# Polarfire SoC register map
Vendor: Microchip; File version: 1.0
CPU: Microchip PolarFire SoC 1.0, little endian
Registers are 32-bit, read-write, reset 0x0 unless marked. A register's access mark holds for its fields unless they carry their own. Offsets are from the block's base; [hi:lo] are bit positions; {n}, {i} and the like mark numbered series; 'fields as' and 'values as' point back to an identical list.

## CFG_DDR_SGMII_PHY — CFG_DDR_SGMII_PHY Controller
Base 0x20007000
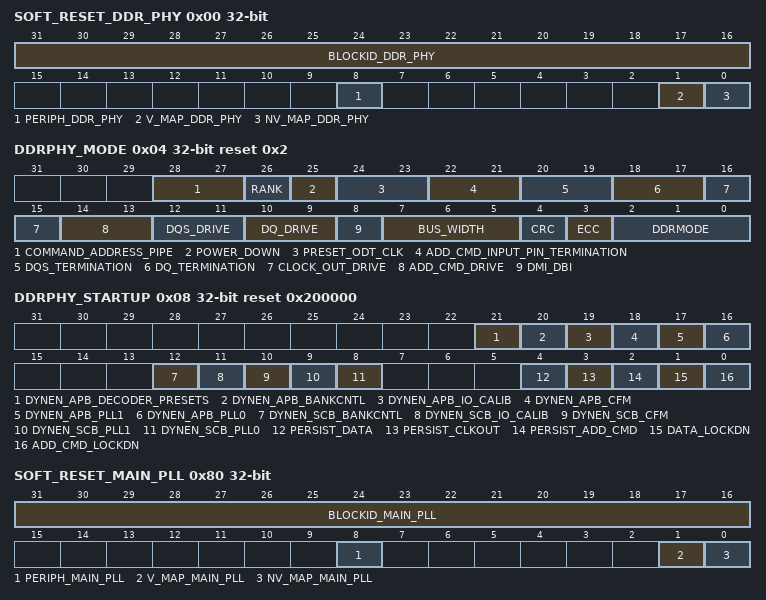
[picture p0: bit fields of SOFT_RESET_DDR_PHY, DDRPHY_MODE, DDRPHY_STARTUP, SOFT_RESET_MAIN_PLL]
0x00 SOFT_RESET_DDR_PHY — Compulsory register for all SCB slaves, facilitating global soft reset.
  [31:16] BLOCKID_DDR_PHY ro — This returns the block type and chip location. The form of BLOCKID = {4'h0, SLVTYPE, CHIPID, SUBID}. SLVTYPE=4'h2 for PCIESS MAIN. CHIPID=4'h0 for PCIESS. SUBID=4'h4 for the MAIN page.
  [8] PERIPH_DDR_PHY — This asserts functional reset of the peripheral block. It is asserted and left asserted at power-up. Write 0 Write 1
  [1] V_MAP_DDR_PHY — Resets all the volatile register bits. Write 0 Write 1
  [0] NV_MAP_DDR_PHY — Resets all the non-volatile register bits (e.g. RW-P bits). Write 0 Write 1
0x04 DDRPHY_MODE reset 0x2
  [28:27] COMMAND_ADDRESS_PIPE — Added Command/Address pipelining
  [26] RANK — select rank
  [25] POWER_DOWN — Power down DDR PHY
  [24:23] PRESET_ODT_CLK — Default, +1,+2, -1 increment settings
  [22:21] ADD_CMD_INPUT_PIN_TERMINATION — Default, +1,+2, -1 increment settings
  [20:19] DQS_TERMINATION — Default, +1,+2, -1 increment settings
  [18:17] DQ_TERMINATION — Default, +1,+2, -1 increment settings
  [16:15] CLOCK_OUT_DRIVE — Default, +1,+2, -1 increment settings
  [14:13] ADD_CMD_DRIVE — Default, +1,+2, -1 increment settings
  [12:11] DQS_DRIVE — Default, +1,+2, -1 increment settings
  [10:9] DQ_DRIVE — Default, +1,+2, -1 increment settings
  [8] DMI_DBI — Data mask or Data bus inversion on/off
  [7:5] BUS_WIDTH — DDR bus width (16 or 32)
  [4] CRC — CRC on/off
  [3] ECC — ECC on/off
  [2:0] DDRMODE — DDR3, DDR3L, DDR4, LPDDR3, LPDDR4 decode. "000 ddr3 001 ddr33L 010 ddr4 011 LPDDR3 100 LPDDR4"
0x08 DDRPHY_STARTUP reset 0x200000
  [21] DYNEN_APB_DECODER_PRESETS — Enable APB DECODER PRESET bit over rides
  [20] DYNEN_APB_BANKCNTL — Enable APB BANKCNTL bit over rides
  [19] DYNEN_APB_IO_CALIB — Enable APB IO CALIB bit over rides
  [18] DYNEN_APB_CFM — Enable APB CFM bit over rides
  [17] DYNEN_APB_PLL1 — Enable APB PLL1 bit over rides
  [16] DYNEN_APB_PLL0 — Enable APB PLL0 bit over rides
  [12] DYNEN_SCB_BANKCNTL — Enable SCB BANKCNTL bit over rides
  [11] DYNEN_SCB_IO_CALIB — Enable SCB IO CALIB bit over rides
  [10] DYNEN_SCB_CFM — Enable SCB CFM bit over rides
  [9] DYNEN_SCB_PLL1 — Enable SCB PLL1 bit over rides
  [8] DYNEN_SCB_PLL0 — Enable SCB PLL0 bit over rides
  [4] PERSIST_DATA — Persist all DATA Dqa dn DQS bits. When 1: write RPC_lp_persist_dqs to 1 write RPC_lp_persist_dqsp to 1 write RPC_lp_persist_dqsn to 1 else 0
  [3] PERSIST_CLKOUT — Persist all clkout bits. When 1: write RPC_lp_persist_clkp to 1 write RPC_lp_persist_clkn to 1 else 0
  [2] PERSIST_ADD_CMD — Persit all Addcmd bits . When 1: write RPC_lp_persist_addcmd to 1 else 0
  [1] DATA_LOCKDN — Data bits honor Lockdn clobal signal
  [0] ADD_CMD_LOCKDN — Addcmd bits honor Lockdn global signal
0x0C SPARE_0 — spare logic
  [15:0] SPARE_0 — Spare register bits
0x80 SOFT_RESET_MAIN_PLL — This is a compulsory register for all SCB slaves and must be at the same offset in all slaves to facilitate global soft reset of all SCB registers with a single broadcast write from the SCB master.
  [31:16] BLOCKID_MAIN_PLL ro — This returns the block type and chip location. (IO SCB bus only) Read 0x0000
  [8] PERIPH_MAIN_PLL — This asserts the functional reset of the block. It is asserted at power up. When written is stays asserted until written to 0. Write 0 Write 1
  [1] V_MAP_MAIN_PLL — This when asserted resets all the register bits apart from the non-volatile registers@ the bit self clears. i.e. is similar to a W1P bit Write 0 Write 1
  [0] NV_MAP_MAIN_PLL — This when asserted resets all the non-volatile register bits e.g. RW-P bits@ the bit self clears i.e. is similar to a W1P bit Write 0 Write 1
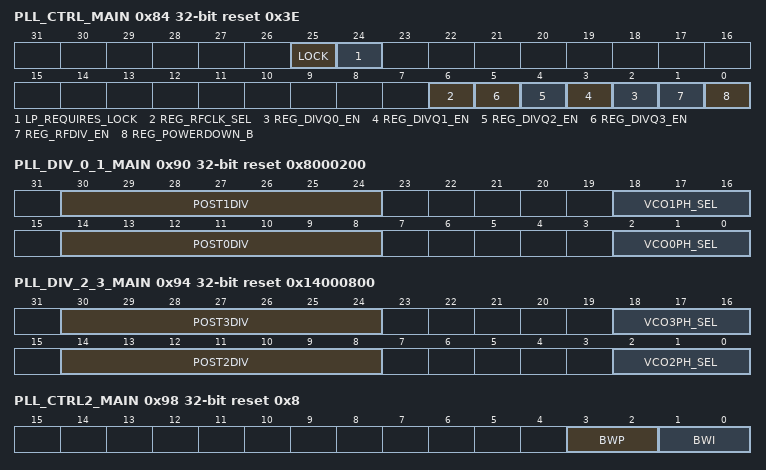
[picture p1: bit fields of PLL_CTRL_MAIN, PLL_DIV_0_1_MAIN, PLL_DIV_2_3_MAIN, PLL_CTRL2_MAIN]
0x84 PLL_CTRL_MAIN reset 0x3E — PLL control register
  [25] LOCK ro — Status of PLL lock
  [24] LP_REQUIRES_LOCK
  [6] REG_RFCLK_SEL
  [n+2] REG_DIVQ{n}_EN (n=0..3)
  [1] REG_RFDIV_EN
  [0] REG_POWERDOWN_B
0x88 PLL_REF_FB_MAIN reset 0x100 — PLL reference and feedback registers
  [13:8] RFDIV
0x8C PLL_FRACN_MAIN ro — PLL fractional register
0x90 PLL_DIV_0_1_MAIN reset 0x8000200 — PLL 0/1 division registers
  [30:24] POST1DIV, [18:16] VCO1PH_SEL ro, [14:8] POST0DIV, [2:0] VCO0PH_SEL ro
0x94 PLL_DIV_2_3_MAIN reset 0x14000800 — PLL 2/3 division registers
  [30:24] POST3DIV, [18:16] VCO3PH_SEL ro, [14:8] POST2DIV, [2:0] VCO2PH_SEL ro
0x98 PLL_CTRL2_MAIN reset 0x8 — PLL control register
  [3:2] BWP, [1:0] BWI
0x9C PLL_CAL_MAIN ro — PLL calibration register
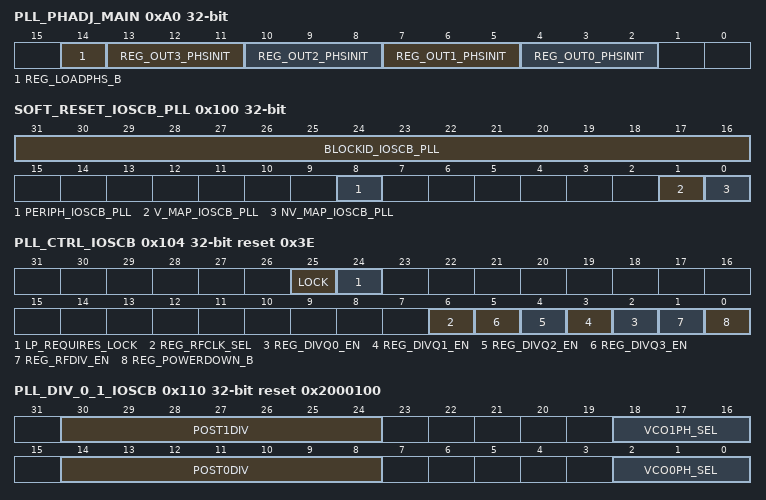
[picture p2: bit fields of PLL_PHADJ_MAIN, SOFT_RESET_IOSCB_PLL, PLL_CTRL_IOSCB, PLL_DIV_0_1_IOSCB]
0xA0 PLL_PHADJ_MAIN — PLL phase registers
  [14] REG_LOADPHS_B, [3n+4:3n+2] REG_OUT{n}_PHSINIT (n=0..3)
0xA4 SSCG_REG_0_MAIN ro — SSCG registers 0
0xA8 SSCG_REG_1_MAIN ro — SSCG registers 1
0xAC SSCG_REG_2_MAIN reset 0x30 — SSCG registers 2
  [11:0] INTIN
0xB0 SSCG_REG_3_MAIN ro — SSCG registers 3
0xB4 RPC_RESET_MAIN_PLL
  [0] SOFT_RESET_PERIPH_MAIN_PLL — RPC reset register
0x100 SOFT_RESET_IOSCB_PLL — This is a compulsory register for all SCB slaves and must be at the same offset in all slaves to facilitate global soft reset of all SCB registers with a single broadcast write from the SCB master.
  [31:16] BLOCKID_IOSCB_PLL ro — This returns the block type and chip location. (IO SCB bus only) Read 0x0000
  [8] PERIPH_IOSCB_PLL — This asserts the functional reset of the block. It is asserted at power up. When written is stays asserted until written to 0. Write 0 Write 1
  [1] V_MAP_IOSCB_PLL — This when asserted resets all the register bits apart from the non-volatile registers@ the bit self clears. i.e. is similar to a W1P bit Write 0 Write 1
  [0] NV_MAP_IOSCB_PLL — This when asserted resets all the non-volatile register bits e.g. RW-P bits@ the bit self clears i.e. is similar to a W1P bit Write 0 Write 1
0x104 PLL_CTRL_IOSCB reset 0x3E — PLL control register
  fields as PLL_CTRL_MAIN
0x108 PLL_REF_FB_IOSCB reset 0x100 — PLL reference and feedback registers
  [13:8] RFDIV
0x10C PLL_FRACN_IOSCB ro — PLL fractional register
0x110 PLL_DIV_0_1_IOSCB reset 0x2000100 — PLL 0/1 division registers
  fields as PLL_DIV_0_1_MAIN
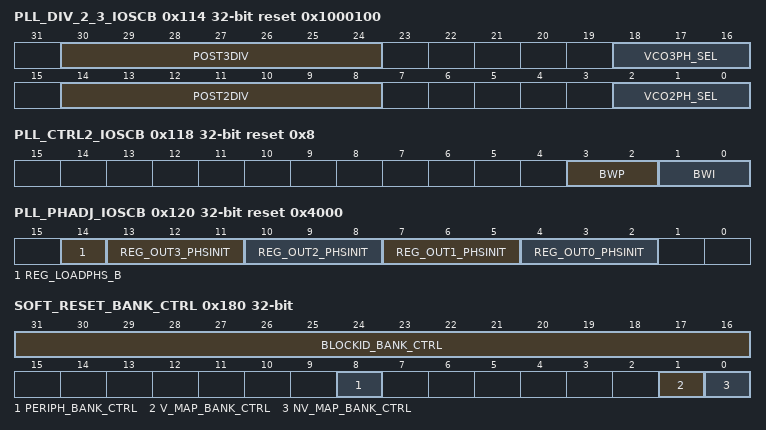
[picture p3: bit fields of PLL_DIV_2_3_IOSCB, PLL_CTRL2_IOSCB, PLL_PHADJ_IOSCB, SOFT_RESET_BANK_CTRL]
0x114 PLL_DIV_2_3_IOSCB reset 0x1000100 — PLL 2/3 division registers
  fields as PLL_DIV_2_3_MAIN
0x118 PLL_CTRL2_IOSCB reset 0x8 — PLL control register
  [3:2] BWP, [1:0] BWI
0x11C PLL_CAL_IOSCB ro — PLL calibration register
0x120 PLL_PHADJ_IOSCB reset 0x4000 — PLL phase registers
  [14] REG_LOADPHS_B, [3n+4:3n+2] REG_OUT{n}_PHSINIT (n=0..3)
0x124 SSCG_REG_0_IOSCB ro — SSCG registers 0
0x128 SSCG_REG_1_IOSCB ro — SSCG registers 1
0x12C SSCG_REG_2_IOSCB reset 0x20 — SSCG registers 2
  [11:0] INTIN
0x130 SSCG_REG_3_IOSCB ro — SSCG registers 3
0x134 RPC_RESET_IOSCB
  [0] SOFT_RESET_PERIPH_IOSCB — RPC reset register
0x180 SOFT_RESET_BANK_CTRL — This is a compulsory register for all SCB slaves and must be at the same offset in all slaves to facilitate global soft reset of all SCB registers with a single broadcast write from the SCB master.
  [31:16] BLOCKID_BANK_CTRL ro — This returns the block type and chip location. (IO SCB bus only) Read 0x0000
  [8] PERIPH_BANK_CTRL — This asserts the functional reset of the block. It is asserted at power up. When written is stays asserted until written to 0. Write 0 Write 1
  [1] V_MAP_BANK_CTRL — This when asserted resets all the register bits apart from the non-volatile registers@ the bit self clears. i.e. is similar to a W1P bit Write 0 Write 1
  [0] NV_MAP_BANK_CTRL — This when asserted resets all the non-volatile register bits e.g. RW-P bits@ the bit self clears i.e. is similar to a W1P bit Write 0 Write 1
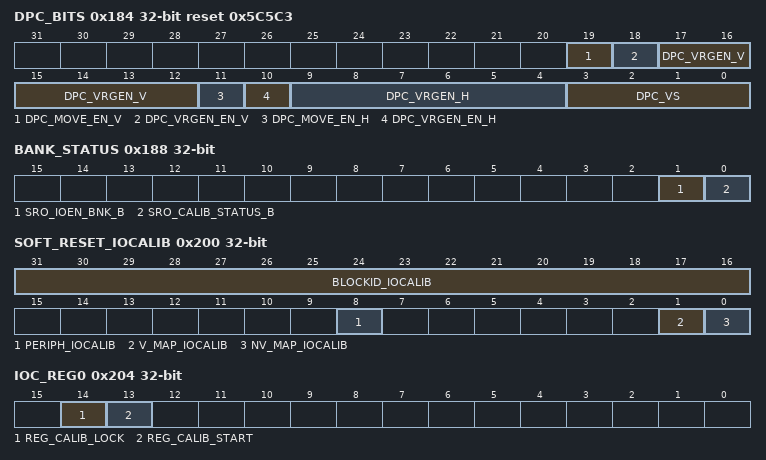
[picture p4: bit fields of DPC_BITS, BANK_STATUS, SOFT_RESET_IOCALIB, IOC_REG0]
0x184 DPC_BITS reset 0x5C5C3
  [19] DPC_MOVE_EN_V — enable dynamic control of vrgen circuit for ADDCMD pins
  [18] DPC_VRGEN_EN_V — enable vref generator for ADDCMD pins
  [17:12] DPC_VRGEN_V — reference voltage ratio setting for ADDCMD pins
  [11] DPC_MOVE_EN_H — enable dynamic control of vrgen circuit for DQ/DQS pins
  [10] DPC_VRGEN_EN_H — enable vref generator for DQ/DQS pins
  [9:4] DPC_VRGEN_H — reference voltage ratio setting for DQ/DQS pins
  [3:0] DPC_VS — bank voltage select for pvt calibration
0x188 BANK_STATUS ro — Bank Complete Registers
  [1] SRO_IOEN_BNK_B — Bank power on complete (active low for polling)
  [0] SRO_CALIB_STATUS_B — Bank calibration complete (active low for polling)
0x18C RPC_RESET_BANK_CTRL
  [0] SOFT_RESET_PERIPH_BANK_CTRL — RPC reset register
0x200 SOFT_RESET_IOCALIB — This is a compulsory register for all SCB slaves and must be at the same offset in all slaves to facilitate global soft reset of all SCB registers with a single broadcast write from the SCB master.
  [31:16] BLOCKID_IOCALIB ro — This returns the block type and chip location. (IO SCB bus only) Read 0x0000
  [8] PERIPH_IOCALIB — This asserts the functional reset of the block. It is asserted at power up. When written is stays asserted until written to 0. Write 0 Write 1
  [1] V_MAP_IOCALIB — This when asserted resets all the register bits apart from the non-volatile registers@ the bit self clears. i.e. is similar to a W1P bit Write 0 Write 1
  [0] NV_MAP_IOCALIB — This when asserted resets all the non-volatile register bits e.g. RW-P bits@ the bit self clears i.e. is similar to a W1P bit Write 0 Write 1
0x204 IOC_REG0 — IO calib control register0
  [14] REG_CALIB_LOCK, [13] REG_CALIB_START
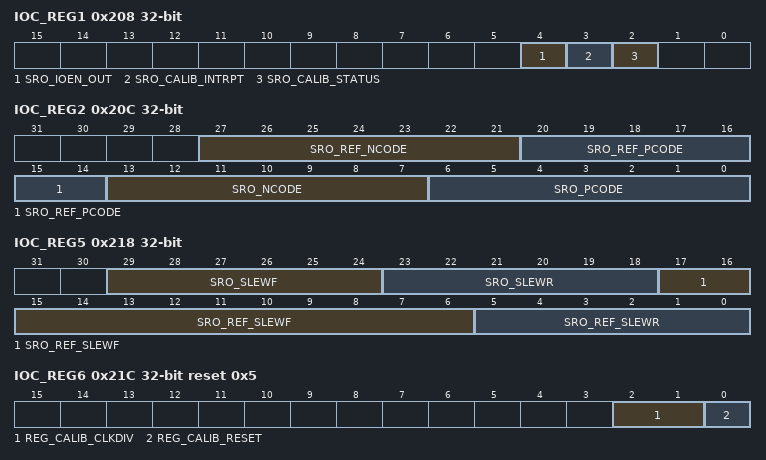
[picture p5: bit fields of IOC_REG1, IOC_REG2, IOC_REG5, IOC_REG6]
0x208 IOC_REG1 ro — IO calib control register1
  [4] SRO_IOEN_OUT, [3] SRO_CALIB_INTRPT, [2] SRO_CALIB_STATUS
0x20C IOC_REG2 ro — IO calib control register2
  [27:21] SRO_REF_NCODE, [20:14] SRO_REF_PCODE, [13:7] SRO_NCODE, [6:0] SRO_PCODE
0x210 IOC_REG3 ro — IO calib control register3
0x214 IOC_REG4 ro — IO calib control register4
0x218 IOC_REG5 ro — IO calib control register5
  [29:24] SRO_SLEWF, [23:18] SRO_SLEWR, [17:6] SRO_REF_SLEWF, [5:0] SRO_REF_SLEWR
0x21C IOC_REG6 reset 0x5 — IO calibr control resgister6
  [2:1] REG_CALIB_CLKDIV, [0] REG_CALIB_RESET
0x220 RPC_RESET_IOCALIB
  [0] SOFT_RESET_PERIPH_IOCALIB — RPC reset register
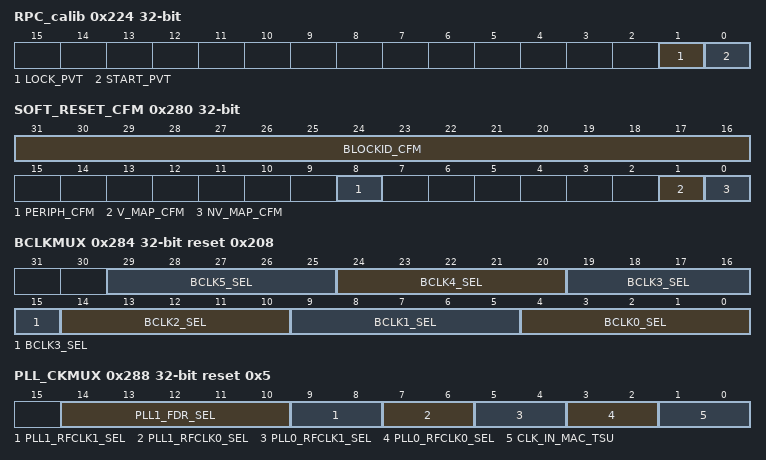
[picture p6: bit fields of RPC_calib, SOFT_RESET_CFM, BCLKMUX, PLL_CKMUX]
0x224 RPC_calib
  [1] LOCK_PVT, [0] START_PVT
0x280 SOFT_RESET_CFM — This is a compulsory register for all SCB slaves and must be at the same offset in all slaves to facilitate global soft reset of all SCB registers with a single broadcast write from the SCB master.
  [31:16] BLOCKID_CFM ro — This returns the block type and chip location. (IO SCB bus only) Read 0x0000
  [8] PERIPH_CFM — This asserts the functional reset of the block. It is asserted at power up. When written is stays asserted until written to 0. Write 0 Write 1
  [1] V_MAP_CFM — This when asserted resets all the register bits apart from the non-volatile registers@ the bit self clears. i.e. is similar to a W1P bit Write 0 Write 1
  [0] NV_MAP_CFM — This when asserted resets all the non-volatile register bits e.g. RW-P bits@ the bit self clears i.e. is similar to a W1P bit Write 0 Write 1
0x284 BCLKMUX reset 0x208 — BCLK mux selections
  [5n+4:5n] BCLK{n}_SEL (n=0..5)
0x288 PLL_CKMUX reset 0x5 — PLL RF clk mux selections
  [14:10] PLL1_FDR_SEL, [9:8] PLL1_RFCLK1_SEL, [7:6] PLL1_RFCLK0_SEL, [5:4] PLL0_RFCLK1_SEL, [3:2] PLL0_RFCLK0_SEL, [1:0] CLK_IN_MAC_TSU
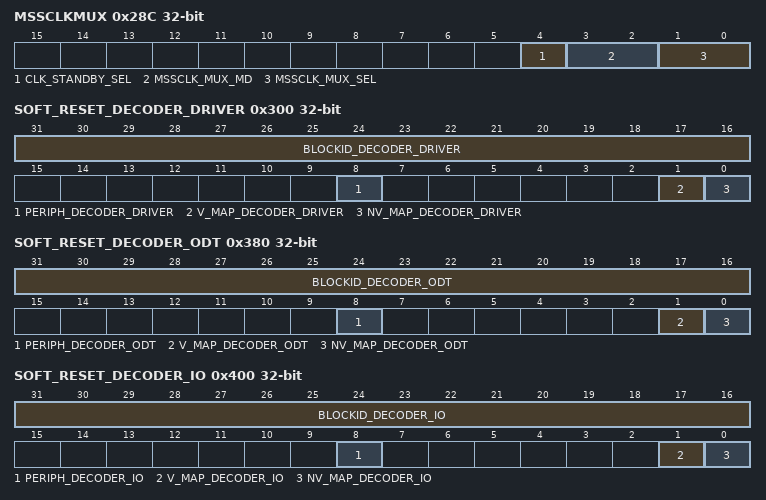
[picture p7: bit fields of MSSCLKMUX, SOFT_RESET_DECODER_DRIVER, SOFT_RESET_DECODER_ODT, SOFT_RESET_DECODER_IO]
0x28C MSSCLKMUX — MSS Clock mux selections
  [4] CLK_STANDBY_SEL, [3:2] MSSCLK_MUX_MD, [1:0] MSSCLK_MUX_SEL
0x290 SPARE0 — spare logic
0x294 FMETER_ADDR ro — Frequency_meter_address_selections
0x298 FMETER_DATAW ro — Frequency_meter_data_write
0x29C FMETER_DATAR ro — Frequency_meter_data_read
0x2A0 TEST_CTRL ro — Test MUX Controls
0x2A4 RPC_RESET_CFM
  [0] SOFT_RESET_PERIPH_CFM — RPC reset register
0x300 SOFT_RESET_DECODER_DRIVER — This is a compulsory register for all SCB slaves and must be at the same offset in all slaves to facilitate global soft reset of all SCB registers with a single broadcast write from the SCB master.
  [31:16] BLOCKID_DECODER_DRIVER ro — This returns the block type and chip location. (IO SCB bus only) Read 0x0000
  [8] PERIPH_DECODER_DRIVER — This asserts the functional reset of the block. It is asserted at power up. When written is stays asserted until written to 0. Write 0 Write 1
  [1] V_MAP_DECODER_DRIVER — This when asserted resets all the register bits apart from the non-volatile registers, the bit self clears. i.e. is similar to a W1P bit Write 0 Write 1
  [0] NV_MAP_DECODER_DRIVER — This when asserted resets all the non-volatile register bits e.g. RW-P bits, the bit self clears i.e. is similar to a W1P bit Write 0 Write 1
0x304 RPC1_DRV
  [3:0] DRV_ADDCMD
0x308 RPC2_DRV
  [3:0] DRV_CLK
0x30C RPC3_DRV
  [3:0] DRV_DQ
0x310 RPC4_DRV
  [3:0] DRV_DQS
0x380 SOFT_RESET_DECODER_ODT — This is a compulsory register for all SCB slaves and must be at the same offset in all slaves to facilitate global soft reset of all SCB registers with a single broadcast write from the SCB master.
  [31:16] BLOCKID_DECODER_ODT ro — This returns the block type and chip location. (IO SCB bus only) Read 0x0000
  [8] PERIPH_DECODER_ODT — This asserts the functional reset of the block. It is asserted at power up. When written is stays asserted until written to 0. Write 0 Write 1
  [1] V_MAP_DECODER_ODT — This when asserted resets all the register bits apart from the non-volatile registers, the bit self clears. i.e. is similar to a W1P bit Write 0 Write 1
  [0] NV_MAP_DECODER_ODT — This when asserted resets all the non-volatile register bits e.g. RW-P bits, the bit self clears i.e. is similar to a W1P bit Write 0 Write 1
0x384 RPC1_ODT
  [3:0] ODT_ADDCMD
0x388 RPC2_ODT
  [3:0] ODT_CLK
0x38C RPC3_ODT
  [3:0] ODT_DQ
0x390 RPC4_ODT
  [3:0] ODT_DQS
0x394 RPC5_ODT
  [0] ODT_DYN_SEL_ADDCMD
0x398 RPC6_ODT
  [0] ODT_DYN_SEL_DATA
0x39C RPC7_ODT
  [2:0] ODT_STATIC_ADDCMD
0x3A0 RPC8_ODT
  [2:0] ODT_STATIC_CLKN
0x3A4 RPC9_ODT
  [2:0] ODT_STATIC_CLKP
0x3A8 RPC10_ODT
  [2:0] ODT_STATIC_DQ
0x3AC RPC11_ODT
  [2:0] ODT_STATIC_DQS
0x400 SOFT_RESET_DECODER_IO — This is a compulsory register for all SCB slaves and must be at the same offset in all slaves to facilitate global soft reset of all SCB registers with a single broadcast write from the SCB master.
  [31:16] BLOCKID_DECODER_IO ro — This returns the block type and chip location. (IO SCB bus only) Read 0x0000
  [8] PERIPH_DECODER_IO — This asserts the functional reset of the block. It is asserted at power up. When written is stays asserted until written to 0. Write 0 Write 1
  [1] V_MAP_DECODER_IO — This when asserted resets all the register bits apart from the non-volatile registers, the bit self clears. i.e. is similar to a W1P bit Write 0 Write 1
  [0] NV_MAP_DECODER_IO — This when asserted resets all the non-volatile register bits e.g. RW-P bits, the bit self clears i.e. is similar to a W1P bit Write 0 Write 1
{0x400+4i} OVRT{i} (i=1..3)
  [11:0] DRV_ADDCMD{i-1}
{0x400+4i} OVRT{i} (i=4..7)
  [11:0] DRV_DATA{i-4}
0x420 OVRT8
  [11:0] DRV_ECC
{0x400+4i} OVRT{i} (i=9..11)
  [11:0] EN_ADDCMD{i-9}
{0x400+4i} OVRT{i} (i=12..15)
  [11:0] EN_DATA{i-12}
0x440 OVRT16
  [11:0] EN_ECC
0x444 RPC17
  [2:0] BCLK_SEL_AC
0x448 RPC18
  [8:0] BCLK_SEL_ADDCMD
0x44C RPC19
  [2:0] BCLK_SEL_CLKN
0x450 RPC20
  [2:0] BCLK_SEL_CLKP
0x454 RPC21
  [8:0] BCLK_SEL_DATA
0x458 RPC22
  [2:0] BCLK_SEL_DQ
0x45C RPC23
  [2:0] BCLK_SEL_DQSN
0x460 RPC24
  [2:0] BCLK_SEL_DQSP
0x464 RPC25
  [1:0] CDR_MD_ADDCMD
0x468 RPC26
  [1:0] CDR_MD_DATA
0x46C RPC27
  [2:0] CLK_MD_ADDCMD
0x470 RPC28
  [11:0] CLK_SEL_ADDCMD
0x474 RPC29
  [11:0] CLK_SEL_DATA
0x478 RPC30
  [1:0] CODE_SEL_ADDCMD
0x47C RPC31
  [1:0] CODE_SEL_DATA
0x480 RPC32
  [0] COMP_ADDCMD
0x484 RPC33
  [0] COMP_CLKN
0x488 RPC34
  [0] COMP_CLKP
0x48C RPC35
  [0] COMP_DQ
0x490 RPC36
  [0] COMP_DQSN
0x494 RPC37
  [0] COMP_DQSP
0x498 RPC38
  [1:0] DIVCLK_SEL_ADDCMD
0x49C RPC39
  [1:0] DIVCLK_SEL_DATA
0x4A0 RPC40
  [2:0] DIV_ADDCMD
0x4A4 RPC41
  [2:0] DIV_DATA
0x4A8 RPC42
  [1:0] DLY_MD_ADDCMD
0x4AC RPC43
  [1:0] DLY_MD_CLKN
0x4B0 RPC44
  [1:0] DLY_MD_CLKP
0x4B4 RPC45
  [1:0] DLY_MD_DQ
0x4B8 RPC46
  [1:0] DLY_MD_DQSN
0x4BC RPC47
  [1:0] DLY_MD_DQSP
0x4C0 RPC48
  [2:0] DQS_MD_DATA
0x4C4 RPC49
  [0] DYNEN_ADDCMD
0x4C8 RPC50
  [0] DYNEN_DATA
0x4CC RPC51
  [0] DYNEN_SOFT_RESET_ADDCMD
0x4D0 RPC52
  [0] DYNEN_SOFT_RESET_DATA
0x4D4 RPC53
  [0] EDGEDET_ADDCMD
0x4D8 RPC54
  [0] EDGEDET_CLKN
0x4DC RPC55
  [0] EDGEDET_CLKP
0x4E0 RPC56
  [0] EDGEDET_DQ
0x4E4 RPC57
  [0] EDGEDET_DQSN
0x4E8 RPC58
  [0] EDGEDET_DQSP
0x4EC RPC59
  [2:0] EYEWIDTH_ADDCMD
0x4F0 RPC60
  [2:0] EYEWIDTH_CLKN
0x4F4 RPC61
  [2:0] EYEWIDTH_CLKP
0x4F8 RPC62
  [2:0] EYEWIDTH_DQ
0x4FC RPC63
  [2:0] EYEWIDTH_DQSN
0x500 RPC64
  [2:0] EYEWIDTH_DQSP
0x504 RPC65
  [0] EYEWIDTH_SEL_ADDCMD
0x508 RPC66
  [0] EYEWIDTH_SEL_CLKN
0x50C RPC67
  [0] EYEWIDTH_SEL_CLKP
0x510 RPC68
  [0] EYEWIDTH_SEL_DQ
0x514 RPC69
  [0] EYEWIDTH_SEL_DQSN
0x518 RPC70
  [0] EYEWIDTH_SEL_DQSP
0x51C RPC71
  [0] EYE_EN_ADDCMD
0x520 RPC72
  [0] EYE_EN_CLKN
0x524 RPC73
  [0] EYE_EN_CLKP
0x528 RPC74
  [0] EYE_EN_DQ
0x52C RPC75
  [0] EYE_EN_DQSN
0x530 RPC76
  [0] EYE_EN_DQSP
0x534 RPC77
  [0] EYE_SDR_ADDCMD
0x538 RPC78
  [0] EYE_SDR_CLKN
0x53C RPC79
  [0] EYE_SDR_CLKP
0x540 RPC80
  [0] EYE_SDR_DQ
0x544 RPC81
  [0] EYE_SDR_DQSN
0x548 RPC82
  [0] EYE_SDR_DQSP
0x54C RPC83
  [0] FIFOWE_ADDCMD
0x550 RPC84
  [0] FIFOWE_CLKN
0x554 RPC85
  [0] FIFOWE_CLKP
0x558 RPC86
  [0] FIFOWE_DQ
0x55C RPC87
  [0] FIFOWE_DQSN
0x560 RPC88
  [0] FIFOWE_DQSP
0x564 RPC89
  [0] FIFO_EN_ADDCMD
0x568 RPC90
  [0] FIFO_EN_DATA
0x56C RPC91
  [0] FIFO_RUN_ADDCMD
0x570 RPC92
  [0] FIFO_RUN_DATA
0x574 RPC93
  [0] GSR_DISABLE_ADDCMD
0x578 RPC94
  [0] GSR_DISABLE_DATA
0x57C RPC95
  [2:0] IBUFMD_ADDCMD
0x580 RPC96
  [2:0] IBUFMD_CLK
0x584 RPC97
  [2:0] IBUFMD_DQ
0x588 RPC98
  [2:0] IBUFMD_DQS
0x58C RPC99
  [1:0] INDLY_SEL_ADDCMD
0x590 RPC100
  [1:0] INDLY_SEL_CLKN
0x594 RPC101
  [1:0] INDLY_SEL_CLKP
0x598 RPC102
  [1:0] INDLY_SEL_DQ
0x59C RPC103
  [1:0] INDLY_SEL_DQSN
0x5A0 RPC104
  [1:0] INDLY_SEL_DQSP
0x5A4 RPC105
  [0] LANE_PVT_ADDCMD
0x5A8 RPC106
  [0] LANE_PVT_DATA
0x5AC RPC107
  [0] LSR_DISABLE_ADDCMD
0x5B0 RPC108
  [0] LSR_DISABLE_CLKN
0x5B4 RPC109
  [0] LSR_DISABLE_CLKP
0x5B8 RPC110
  [0] LSR_DISABLE_DQ
0x5BC RPC111
  [0] LSR_DISABLE_DQSN
0x5C0 RPC112
  [0] LSR_DISABLE_DQSP
0x5C4 RPC113
  [0] MVDLY_EN_ADDCMD
0x5C8 RPC114
  [0] MVDLY_EN_CLKN
0x5CC RPC115
  [0] MVDLY_EN_CLKP
0x5D0 RPC116
  [0] MVDLY_EN_DQ
0x5D4 RPC117
  [0] MVDLY_EN_DQSN
0x5D8 RPC118
  [0] MVDLY_EN_DQSP
0x5DC RPC119
  [0] OECLK_INV_ADDCMD
0x5E0 RPC120
  [0] OECLK_INV_CLKN
0x5E4 RPC121
  [0] OECLK_INV_CLKP
0x5E8 RPC122
  [0] OECLK_INV_DQ
0x5EC RPC123
  [0] OECLK_INV_DQSN
0x5F0 RPC124
  [0] OECLK_INV_DQSP
0x5F4 RPC125
  [2:0] OE_MD_ADDCMD
0x5F8 RPC126
  [2:0] OE_MD_CLKN
0x5FC RPC127
  [2:0] OE_MD_CLKP
0x600 RPC128
  [2:0] OE_MD_DQ
0x604 RPC129
  [2:0] OE_MD_DQSN
0x608 RPC130
  [2:0] OE_MD_DQSP
0x60C RPC131
  [0] PAUSE_EN_ADDCMD
0x610 RPC132
  [0] PAUSE_EN_DATA
0x614 RPC133
  [0] QDR_ADDCMD
0x618 RPC134
  [0] QDR_DATA
0x61C RPC135
  [0] QDR_MD_ADDCMD
0x620 RPC136
  [0] QDR_MD_CLKN
0x624 RPC137
  [0] QDR_MD_CLKP
0x628 RPC138
  [0] QDR_MD_DQ
0x62C RPC139
  [0] QDR_MD_DQSN
0x630 RPC140
  [0] QDR_MD_DQSP
0x634 RPC141
  [0] RANK2_ADDCMD
0x638 RPC142
  [0] RANK2_DATA
0x63C RPC143
  [0] RST_INV_ADDCMD
0x640 RPC144
  [0] RST_INV_DATA
0x644 RPC145
  [6:0] RXDLY_ADDCMD
0x648 RPC146
  [6:0] RXDLY_CLKN
0x64C RPC147
  [6:0] RXDLY_CLKP
0x650 RPC148
  [0] RXDLY_DIR_ADDCMD
0x654 RPC149
  [0] RXDLY_DIR_DATA
0x658 RPC150
  [6:0] RXDLY_DQ
0x65C RPC151
  [6:0] RXDLY_DQSN
0x660 RPC152
  [6:0] RXDLY_DQSP
0x664 RPC153
  [0] RXDLY_EN_ADDCMD
0x668 RPC154
  [0] RXDLY_EN_DATA
0x66C RPC155
  [7:0] RXDLY_OFFSET_ADDCMD
0x670 RPC156
  [7:0] RXDLY_OFFSET_DATA
0x674 RPC157
  [0] RXDLY_WIDE_ADDCMD
0x678 RPC158
  [0] RXDLY_WIDE_CLKN
0x67C RPC159
  [0] RXDLY_WIDE_CLKP
0x680 RPC160
  [0] RXDLY_WIDE_DQ
0x684 RPC161
  [0] RXDLY_WIDE_DQSN
0x688 RPC162
  [0] RXDLY_WIDE_DQSP
0x68C RPC163
  [0] RXMVDLY_EN_ADDCMD
0x690 RPC164
  [0] RXMVDLY_EN_DATA
0x694 RPC165
  [2:0] RXPTR_ADDCMD
0x698 RPC166
  [2:0] RXPTR_DATA
0x69C RPC167
  [3:0] RX_MD_ADDCMD
0x6A0 RPC168
  [3:0] RX_MD_CLKN
0x6A4 RPC169
  [3:0] RX_MD_CLKP
0x6A8 RPC170
  [3:0] RX_MD_DQ
0x6AC RPC171
  [3:0] RX_MD_DQSN
0x6B0 RPC172
  [3:0] RX_MD_DQSP
0x6B4 RPC173
  [0] SCLK0_EN_ADDCMD
0x6B8 RPC174
  [0] SCLK0_EN_CLKN
0x6BC RPC175
  [0] SCLK0_EN_CLKP
0x6C0 RPC176
  [0] SCLK0_EN_DQ
0x6C4 RPC177
  [0] SCLK0_EN_DQSN
0x6C8 RPC178
  [0] SCLK0_EN_DQSP
0x6CC RPC179
  [0] SCLK0_INV_ADDCMD
0x6D0 RPC180
  [0] SCLK0_INV_CLKN
0x6D4 RPC181
  [0] SCLK0_INV_CLKP
0x6D8 RPC182
  [0] SCLK0_INV_DQ
0x6DC RPC183
  [0] SCLK0_INV_DQSN
0x6E0 RPC184
  [0] SCLK0_INV_DQSP
0x6E4 RPC185
  [0] SCLK1_EN_ADDCMD
0x6E8 RPC186
  [0] SCLK1_EN_CLKN
0x6EC RPC187
  [0] SCLK1_EN_CLKP
0x6F0 RPC188
  [0] SCLK1_EN_DQ
0x6F4 RPC189
  [0] SCLK1_EN_DQSN
0x6F8 RPC190
  [0] SCLK1_EN_DQSP
0x6FC RPC191
  [0] SCLK1_INV_ADDCMD
0x700 RPC192
  [0] SCLK1_INV_CLKN
0x704 RPC193
  [0] SCLK1_INV_CLKP
0x708 RPC194
  [0] SCLK1_INV_DQ
0x70C RPC195
  [0] SCLK1_INV_DQSN
0x710 RPC196
  [0] SCLK1_INV_DQSP
0x714 RPC197
  [0] SOFT_RESET_ADDCMD
0x718 RPC198
  [0] SOFT_RESET_DATA
0x71C RPC199
  [0] SPARE_IOG_ADDCMD
0x720 RPC200
  [0] SPARE_IOG_CLKN
0x724 RPC201
  [0] SPARE_IOG_CLKP
0x728 RPC202
  [0] SPARE_IOG_DQ
0x72C RPC203
  [0] SPARE_IOG_DQSN
0x730 RPC204
  [0] SPARE_IOG_DQSP
0x734 RPC205
  [1:0] SPIO_SEL_DI_DQSN
0x738 RPC206
  [1:0] SPIO_SEL_DI_DQSP
0x73C RPC207
  [1:0] STOP_SEL_ADDCMD
0x740 RPC208
  [1:0] STOP_SEL_DATA
0x744 RPC209
  [1:0] TXCLK_SEL_ADDCMD
0x748 RPC210
  [1:0] TXCLK_SEL_CLKN
0x74C RPC211
  [1:0] TXCLK_SEL_CLKP
0x750 RPC212
  [1:0] TXCLK_SEL_DQ
0x754 RPC213
  [1:0] TXCLK_SEL_DQSN
0x758 RPC214
  [1:0] TXCLK_SEL_DQSP
0x75C RPC215
  [6:0] TXDLY_ADDCMD
0x760 RPC216
  [6:0] TXDLY_CLKN
0x764 RPC217
  [6:0] TXDLY_CLKP
0x768 RPC218
  [0] TXDLY_DIR_ADDCMD
0x76C RPC219
  [0] TXDLY_DIR_DATA
0x770 RPC220
  [6:0] TXDLY_DQ
0x774 RPC221
  [6:0] TXDLY_DQSN
0x778 RPC222
  [6:0] TXDLY_DQSP
0x77C RPC223
  [0] TXDLY_EN_ADDCMD
0x780 RPC224
  [0] TXDLY_EN_DATA
0x784 RPC225
  [7:0] TXDLY_OFFSET_ADDCMD
0x788 RPC226
  [7:0] TXDLY_OFFSET_DATA
0x78C RPC227
  [0] TXMVDLY_EN_ADDCMD
0x790 RPC228
  [0] TXMVDLY_EN_DATA
0x794 RPC229
  [6:0] TX_MD_ADDCMD
0x798 RPC230
  [6:0] TX_MD_CLKN
0x79C RPC231
  [6:0] TX_MD_CLKP
0x7A0 RPC232
  [6:0] TX_MD_DQ
0x7A4 RPC233
  [6:0] TX_MD_DQSN
0x7A8 RPC234
  [6:0] TX_MD_DQSP
{0x400+4i} RPC{i} (i=235..237)
  [11:0] WPD_ADDCMD{i-235}
{0x400+4i} RPC{i} (i=238..241)
  [11:0] WPD_DATA{i-238}
0x7C8 RPC242
  [11:0] WPD_ECC
{0x400+4i} RPC{i} (i=243..245)
  [11:0] WPU_ADDCMD{i-243}
{0x400+4i} RPC{i} (i=246..249)
  [11:0] WPU_DATA{i-246}
0x7E8 RPC250
  [11:0] WPU_ECC
{0x400+4i} SPIO{i} (i=251..253)
  [0] SEL_REFCLK{i-251}
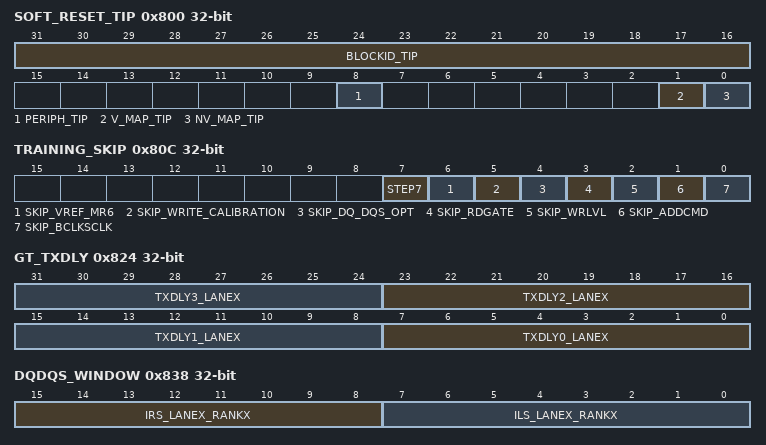
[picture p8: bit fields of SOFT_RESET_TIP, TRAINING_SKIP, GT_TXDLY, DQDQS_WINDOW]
0x800 SOFT_RESET_TIP — Compulsory register for all SCB slaves, facilitating global soft reset.
  [31:16] BLOCKID_TIP ro — This returns the block type and chip location. The form of BLOCKID = {4'h0, SLVTYPE, CHIPID, SUBID}. SLVTYPE=4'h2 for PCIESS MAIN. CHIPID=4'h0 for PCIESS. SUBID=4'h4 for the MAIN page.
  [8] PERIPH_TIP — This asserts functional reset of the peripheral block. It is asserted and left asserted at power-up. Write 0 Write 1
  [1] V_MAP_TIP — Resets all the volatile register bits. Write 0 Write 1
  [0] NV_MAP_TIP — Resets all the non-volatile register bits (e.g. RW-P bits). Write 0 Write 1
0x804 rank_select — select rank 0 or 1
  [0] RANK — TIP readback rank select
0x808 LANE_SELECT — select lane 0, 1, 2, 3 or 4
  [2:0] LANE — TIP readback lane select
0x80C TRAINING_SKIP — skip
  [7] STEP7
  [6] SKIP_VREF_MR6 — 0 -> do not skip SET VREF 1 -> skip SET VREF
  [5] SKIP_WRITE_CALIBRATION — 0 -> do not skip WRITE CALIBRATION 1 -> skip WRITE CALIBRATION
  [4] SKIP_DQ_DQS_OPT — 0 -> do not skip DQ/DQS Optimization 1 -> skip DQ/DQS Optimization
  [3] SKIP_RDGATE — 0 -> do not skip READ GATE TRAINING 1 -> skip READ GATE TRAINING
  [2] SKIP_WRLVL — 0 -> do not skip WRITE LEVELING 1 -> skip WRITE LEVELING
  [1] SKIP_ADDCMD — 0 -> do not skip ADDRESS/CMD training 1 -> skip ADDRESS/CMD training
  [0] SKIP_BCLKSCLK — 0 -> do not skip BCLK/SCLK training 1 -> skip BCLK/SCLK training
0x810 TRAINING_START — start
  [0] START — Starts training on 0->1 transition
0x814 TRAINING_STATUS ro — status
  [7:0] STATUS — Returns 1 on completion of non-skipped trainings.
0x818 TRAINING_RESET — reset
  [0] RESET — Resets the TIP state machines.
0x81C GT_ERR_COMB ro — set lane register
  [5:0] ERROR_COMB_LANEX — TIP readback gate training error flags bit 0 = initial burst error rank0 bit 1 = initial burst error rank1 bit 2 = Out of Range error rank0 bit 3 = Out of Range error rank1 bit 4 = no burst error rank0 bit 5 = no burst error rank1
0x820 GT_CLK_SEL ro — set lane/rank register
  [2:0] CLK_SEL_LANEX_RANKX — TIP readback gate training clk_sel result
0x824 GT_TXDLY ro
  [8n+7:8n] TXDLY{n}_LANEX (n=0..3) — TIP readback gate training txdly @ clk_sel={n}
0x828 GT_STEPS_180 ro — set lane/rank register
  [3:0] STEPS_180_LANEX_RANKX — TIP readback gate training steps_180
0x82C GT_STATE ro — set lane register
  [3:0] GT_STATE_LANEX — TIP readback gate training state
0x830 wl_delay_0 ro — set lane/rank register
  [7:0] WLDELAY_LANEX_RANKX — TIP readback write leveling delay
0x834 DQ_DQS_ERR_DONE ro — set lane/rank register
  [3:0] DQ_DQS_ERROR_DONE_LANEX_RANKX — TIP readback DQ/DQS optimization error flags
0x838 DQDQS_WINDOW ro — set rank register
  [15:8] IRS_LANEX_RANKX — TIP readback DQ/DQS optimization state
  [7:0] ILS_LANEX_RANKX — TIP readback DQ/DQS optimization initial->left side of window delay
0x83C DQDQS_STATE ro — set lane/rank register
  [7:0] STATE_LANEX_RANKX — TIP readback DQ/DQS optimization bit 0 (in lane) RX delay
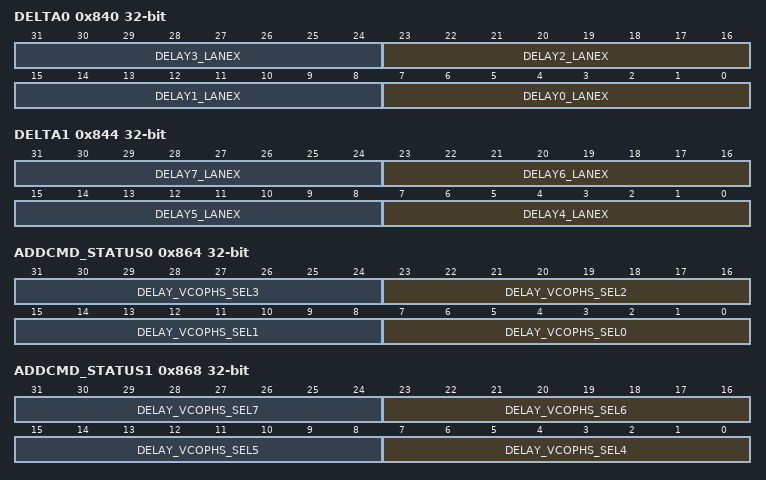
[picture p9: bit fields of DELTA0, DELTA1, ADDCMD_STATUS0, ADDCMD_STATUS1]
0x840 DELTA0 ro — set lane register
  [8n+7:8n] DELAY{n}_LANEX (n=0..3) — TIP readback DQ/DQS optimization bit {n} (in lane) RX delay
0x844 DELTA1 ro — set lane register
  [8n-25:8n-32] DELAY{n}_LANEX (n=4..7) — TIP readback DQ/DQS optimization bit {n} (in lane) RX delay
0x848 DQDQS_STATUS0 ro — set lane register
  [7:0] INIT_DLY_LANEX — Initial delay for right side of window
0x84C DQDQS_STATUS1 ro — set lane/rank register
  [7:0] DQS_DLY_LANEX_RANKX — DQS delay
0x850 DQDQS_STATUS2 ro — set lane register
  [7:0] BIT_WIDTH_LANEX — Data window width
0x854 DQDQS_STATUS3 ro — set lane/rank register
  [7:0] INITLDQS_2_MID_LANEX_RANKX — Distance between the DQS start possition to the middle of data window
0x858 DQDQS_STATUS4 ro — set lane/rank register
  [7:0] MID_2_INITLDQS_LANEX_RANKX — Distance between the calculated middle of the data window and DQS starting on the RHS
0x85C DQDQS_STATUS5 ro — set lane/rank register
  [7:0] STW_2_INITLDQS_LANEX_RANKX — Distance from the start of the data window to the initial DQS position
0x860 DQDQS_STATUS6 ro — set lane/rank register
  [7:0] INITLDQS_2_STW_LANEX_RANKX — Distance between the DQS start position and the start of the data window
0x864 ADDCMD_STATUS0 ro — Output delays at VCOPHS offset values
  [8n+7:8n] DELAY_VCOPHS_SEL{n} (n=0..3) — Output delay @ VCOPHS={45n} degrees
0x868 ADDCMD_STATUS1 ro — Output delays at VCOPHS offset values
  [8n-25:8n-32] DELAY_VCOPHS_SEL{n} (n=4..7) — Output delay @ VCOPHS={45n} degrees
0x86C ADDCMD_ANSWER ro — ADDCMD training result
  [3:0] VCOPHS_SEL_AFTER_TRAINING — Chosen VCOPHS = value * 45 degrees
0x870 BCLKSCLK_ANSWER ro — BCLK/SCLK trainng result
  [3:0] BCLK0_VCOPHS_SEL — BCLK/SCLK training result (45 degree offset count)
0x874 DQDQS_WRCALIB_OFFSET ro — set lane register
  [7:0] WRCALIB_OFFSET_LANEX — WRITE CALIBRATION OFFSET RESULT
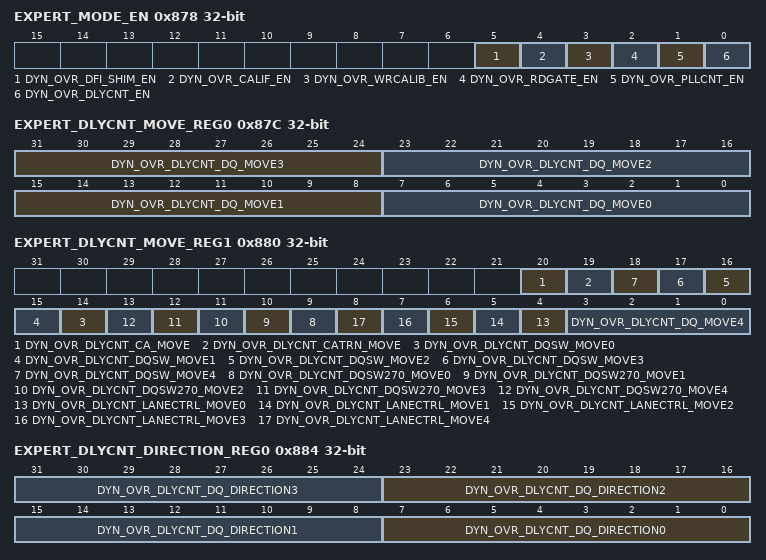
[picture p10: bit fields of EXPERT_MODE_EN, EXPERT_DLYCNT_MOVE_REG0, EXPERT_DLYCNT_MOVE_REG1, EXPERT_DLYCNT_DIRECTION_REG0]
0x878 EXPERT_MODE_EN — enable override of dynamic delay control signals
  [5] DYN_OVR_DFI_SHIM_EN — 1 -> enable MSS overide, 0 -> disable MSS override
  [4] DYN_OVR_CALIF_EN — 1 -> enable MSS overide, 0 -> disable MSS override
  [3] DYN_OVR_WRCALIB_EN — 1 -> enable MSS overide, 0 -> disable MSS override
  [2] DYN_OVR_RDGATE_EN — 1 -> enable MSS overide, 0 -> disable MSS override
  [1] DYN_OVR_PLLCNT_EN — 1 -> enable MSS overide, 0 -> disable MSS override
  [0] DYN_OVR_DLYCNT_EN — 1 -> enable MSS overide, 0 -> disable MSS override
0x87C EXPERT_DLYCNT_MOVE_REG0 — delayline control
  [31:24] DYN_OVR_DLYCNT_DQ_MOVE3 — DQ[31:24] MOVE
  [23:16] DYN_OVR_DLYCNT_DQ_MOVE2 — DQ[23:16] MOVE
  [15:8] DYN_OVR_DLYCNT_DQ_MOVE1 — DQ[15:8] move
  [7:0] DYN_OVR_DLYCNT_DQ_MOVE0 — DQ[7:0] move
0x880 EXPERT_DLYCNT_MOVE_REG1 — delayline control
  [20] DYN_OVR_DLYCNT_CA_MOVE — Command/Address IOG move
  [19] DYN_OVR_DLYCNT_CATRN_MOVE — Command/Address IOG move (training site)
  [n+14] DYN_OVR_DLYCNT_DQSW_MOVE{n} (n=0..4) — dqsw lane {n} move
  [n+9] DYN_OVR_DLYCNT_DQSW270_MOVE{n} (n=0..4) — dqsw270 lane {n} move
  [n+4] DYN_OVR_DLYCNT_LANECTRL_MOVE{n} (n=0..4) — lanectrl lane {n} move
  [3:0] DYN_OVR_DLYCNT_DQ_MOVE4 — DQ[35:32] MOVE
0x884 EXPERT_DLYCNT_DIRECTION_REG0 — delayline control
  [8n+7:8n] DYN_OVR_DLYCNT_DQ_DIRECTION{n} (n=0..3) — DQ[{8n+7}:{8n}] direction
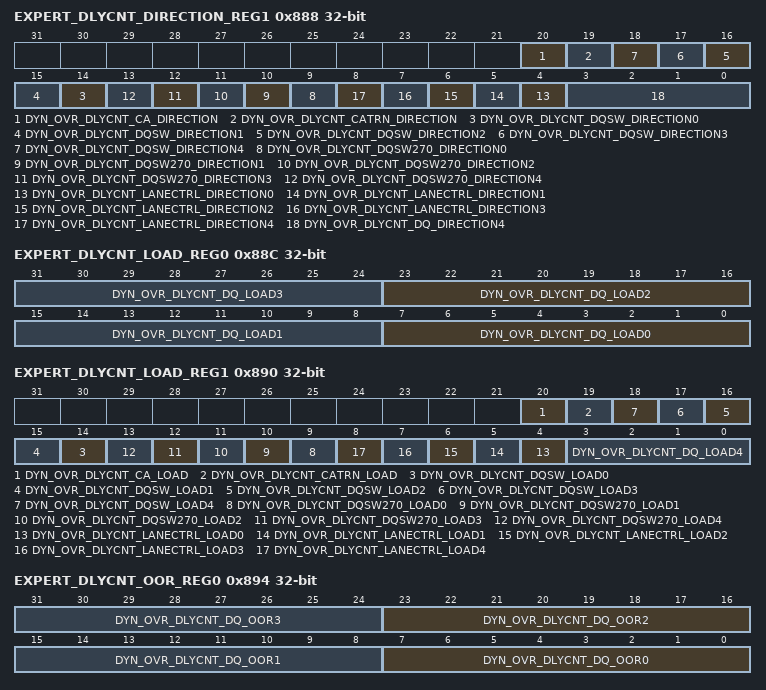
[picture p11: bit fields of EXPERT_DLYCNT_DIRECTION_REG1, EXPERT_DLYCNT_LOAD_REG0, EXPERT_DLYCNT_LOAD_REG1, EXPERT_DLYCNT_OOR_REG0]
0x888 EXPERT_DLYCNT_DIRECTION_REG1 — delayline control
  [20] DYN_OVR_DLYCNT_CA_DIRECTION — Command/Address IOG direction
  [19] DYN_OVR_DLYCNT_CATRN_DIRECTION — Command/Address IOG direction (training site)
  [n+14] DYN_OVR_DLYCNT_DQSW_DIRECTION{n} (n=0..4) — dqsw lane {n} direction
  [n+9] DYN_OVR_DLYCNT_DQSW270_DIRECTION{n} (n=0..4) — dqsw270 lane {n} direction
  [n+4] DYN_OVR_DLYCNT_LANECTRL_DIRECTION{n} (n=0..4) — lanectrl lane {n} direction
  [3:0] DYN_OVR_DLYCNT_DQ_DIRECTION4 — DQ[35:32] direction
0x88C EXPERT_DLYCNT_LOAD_REG0 — delayline control
  [8n+7:8n] DYN_OVR_DLYCNT_DQ_LOAD{n} (n=0..3) — DQ[{8n+7}:{8n}] load
0x890 EXPERT_DLYCNT_LOAD_REG1 — delayline control
  [20] DYN_OVR_DLYCNT_CA_LOAD — Command/Address IOG load
  [19] DYN_OVR_DLYCNT_CATRN_LOAD — Command/Address IOG load (training site)
  [n+14] DYN_OVR_DLYCNT_DQSW_LOAD{n} (n=0..4) — dqsw lane {n} load
  [n+9] DYN_OVR_DLYCNT_DQSW270_LOAD{n} (n=0..4) — dqsw270 lane {n} load
  [n+4] DYN_OVR_DLYCNT_LANECTRL_LOAD{n} (n=0..4) — lanectrl lane {n} load
  [3:0] DYN_OVR_DLYCNT_DQ_LOAD4 — DQ[35:32] load
0x894 EXPERT_DLYCNT_OOR_REG0 ro — delayline control
  [8n+7:8n] DYN_OVR_DLYCNT_DQ_OOR{n} (n=0..3) — DQ[{8n+7}:{8n}] oor
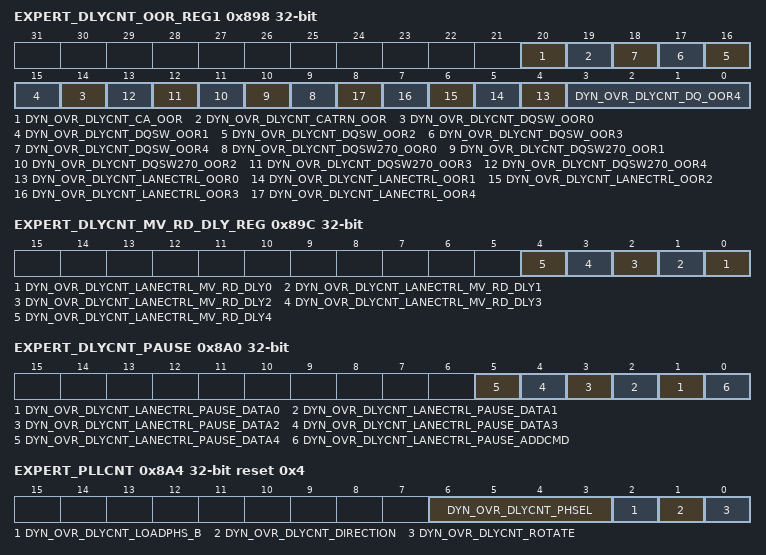
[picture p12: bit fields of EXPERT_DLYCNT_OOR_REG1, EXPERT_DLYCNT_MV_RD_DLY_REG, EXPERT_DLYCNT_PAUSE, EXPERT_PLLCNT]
0x898 EXPERT_DLYCNT_OOR_REG1 ro — delayline control
  [20] DYN_OVR_DLYCNT_CA_OOR — Command/Address IOG oor
  [19] DYN_OVR_DLYCNT_CATRN_OOR — Command/Address IOG oor (training site)
  [n+14] DYN_OVR_DLYCNT_DQSW_OOR{n} (n=0..4) — dqsw lane {n} oor
  [n+9] DYN_OVR_DLYCNT_DQSW270_OOR{n} (n=0..4) — dqsw270 lane {n} oor
  [n+4] DYN_OVR_DLYCNT_LANECTRL_OOR{n} (n=0..4) — lanectrl lane {n} oor
  [3:0] DYN_OVR_DLYCNT_DQ_OOR4 — DQ[35:32] oor
0x89C EXPERT_DLYCNT_MV_RD_DLY_REG — delayline control
  [n] DYN_OVR_DLYCNT_LANECTRL_MV_RD_DLY{n} (n=0..4) — lanectrl lane {n} mv_rd_dly
0x8A0 EXPERT_DLYCNT_PAUSE — lane pause
  [n+1] DYN_OVR_DLYCNT_LANECTRL_PAUSE_DATA{n} (n=0..4) — pause data lane {n}
  [0] DYN_OVR_DLYCNT_LANECTRL_PAUSE_ADDCMD — addcmd lane pause
0x8A4 EXPERT_PLLCNT reset 0x4 — dynamic PLL controls
  [6:3] DYN_OVR_DLYCNT_PHSEL — [0] -> BCLK VCOPHS_SEL [1] -> BCLK90 VCOPHS_SEL [2] -> REFCLK VCOPHS_SEL [3] -> SCLK VCOPHS_SEL
  [2] DYN_OVR_DLYCNT_LOADPHS_B — PLL LOADPHS_B (asynchronous load on 0)
  [1] DYN_OVR_DLYCNT_DIRECTION — PLL ROTATE DIRECTION (1-> add, 0-> subtract)
  [0] DYN_OVR_DLYCNT_ROTATE — PLL PHASE ROTATE (rotates on 0->1 edge)
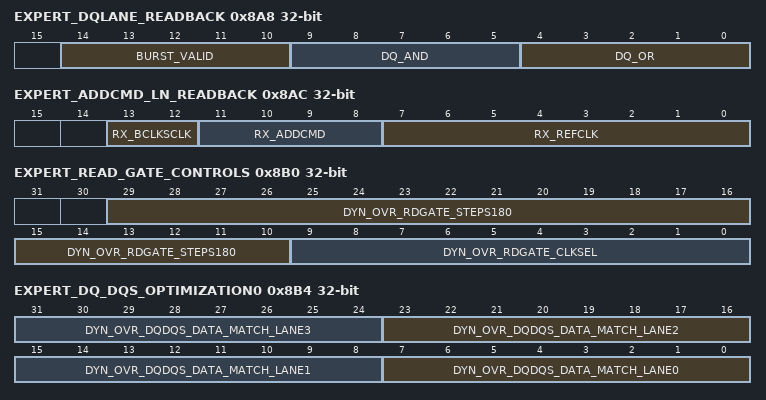
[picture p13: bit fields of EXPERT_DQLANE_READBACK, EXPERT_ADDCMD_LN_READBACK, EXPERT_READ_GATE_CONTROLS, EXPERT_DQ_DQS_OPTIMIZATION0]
0x8A8 EXPERT_DQLANE_READBACK ro — DQ/DQS lane read back signals
  [14:10] BURST_VALID — [0] -> valid burst detected (lane0) [1] -> valid burst detected (lane1) [2] -> valid burst detected (lane2) [3] -> valid burst detected (lane3) [4] -> valid burst detected (lane4)
  [9:5] DQ_AND — [0] -> AND of all DQ bits (lane0) [1] -> AND of all DQ bits (lane1) [2] -> AND of all DQ bits (lane2) [3] -> AND of all DQ bits (lane3) [4] -> AND of all DQ bits (lane4)
  [4:0] DQ_OR — [0] -> OR of all DQ bits (lane0) [1] -> OR of all DQ bits (lane1) [2] -> OR of all DQ bits (lane2) [3] -> OR of all DQ bits (lane3) [4] -> OR of all DQ bits (lane4)
0x8AC EXPERT_ADDCMD_LN_READBACK ro — ADDRESS/COMMAND LANE READBACK
  [13:12] RX_BCLKSCLK — RX from BCLK/SCLK training site
  [11:8] RX_ADDCMD — RX from ADDCMD training site
  [7:0] RX_REFCLK — [3:0] -> RX from CK0 training site [7:4] -> RX from CK1 training site
0x8B0 EXPERT_READ_GATE_CONTROLS — READ GATE TRAINING OVERRIDES
  [29:10] DYN_OVR_RDGATE_STEPS180 — [3:0] lane 0 read gate steps_180 [7:4] lane 1 read gate steps_180 [11:8] lane 2 read gate steps_180 [15:12] lane 3 read gate steps_180 [19:16] lane 4 read gate steps_180
  [9:0] DYN_OVR_RDGATE_CLKSEL — [1:0] lane 0 read gate clk_sel [3:2] lane 1 read gate clk_sel [5:4] lane 2 read gate clk_sel [7:6] lane 3 read gate clk_sel [9:8] lane 4 read gate clk_sel
0x8B4 EXPERT_DQ_DQS_OPTIMIZATION0 ro — DQ/DQS OPTIMIZATION READBACK REG 0
  [8n+7:8n] DYN_OVR_DQDQS_DATA_MATCH_LANE{n} (n=0..3) — [n] -> bit n in lane matches read training pattern
0x8B8 EXPERT_DQ_DQS_OPTIMIZATION1 ro — DQ/DQS OPTIMIZATION READBACK REG 1
  [7:0] DYN_OVR_DQDQS_DATA_MATCH_LANE4 — [n] -> bit n in lane matches read training pattern
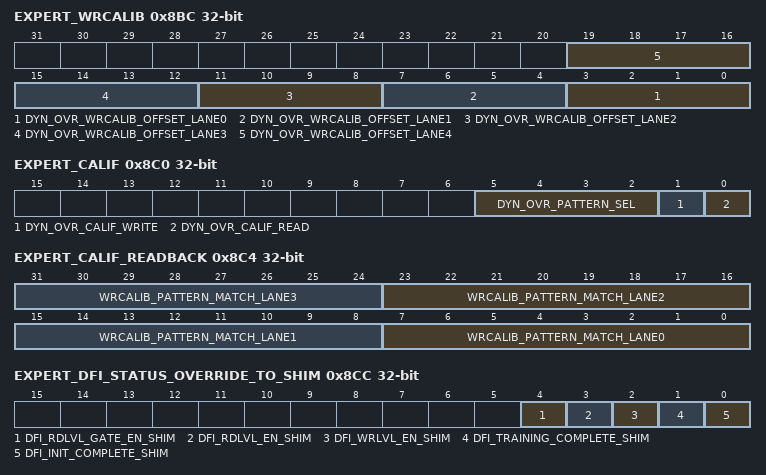
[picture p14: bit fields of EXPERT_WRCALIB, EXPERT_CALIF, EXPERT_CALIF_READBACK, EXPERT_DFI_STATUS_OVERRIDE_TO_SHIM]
0x8BC EXPERT_WRCALIB — WRCALIB OFFSET
  [4n+3:4n] DYN_OVR_WRCALIB_OFFSET_LANE{n} (n=0..4) — write calibration offset lane {n}
0x8C0 EXPERT_CALIF — CAL INTERFACE CONTROL
  [5:2] DYN_OVR_PATTERN_SEL — CAL IF pattern select
  [1] DYN_OVR_CALIF_WRITE — initiate CAL IF write
  [0] DYN_OVR_CALIF_READ — initiate CAL IF read
0x8C4 EXPERT_CALIF_READBACK ro — CAL INTERFACE READBACK0
  [8n+7:8n] WRCALIB_PATTERN_MATCH_LANE{n} (n=0..3) — [n] -> bit n in lane matches selected pattern
0x8C8 EXPERT_CALIF_READBACK1 ro — CAL INTERFACE READBACK1
  [7:0] WRCALIB_PATTERN_MATCH_LANE4 — [n] -> bit n in lane matches selected pattern
0x8CC EXPERT_DFI_STATUS_OVERRIDE_TO_SHIM — DFI signals are used by the SHIM to put signalling in special training modes
  [4] DFI_RDLVL_GATE_EN_SHIM — dfi_rdlvl_en override in shim
  [3] DFI_RDLVL_EN_SHIM — dfi_wrlvl_en override in shim
  [2] DFI_WRLVL_EN_SHIM — dfi_training_complete override in shim
  [1] DFI_TRAINING_COMPLETE_SHIM — dfi_init_complete override in shim
  [0] DFI_INIT_COMPLETE_SHIM — dfi status signals to shim override
0x8D0 TIP_CFG_PARAMS — TIP STATIC PARAMETERS 0
  [30:22] ADDRCMD_WAIT_COUNT — Number of VCO Phase offsets between BCLK and SCLK
  [21:13] READ_GATE_MIN_READS — Number of VCO Phase offsets between BCLK and SCLK
  [12:6] WRCALIB_WRITE_COUNT — Number of VCO Phase offsets between BCLK and SCLK
  [5:3] BCKLSCLK_OFFSET — Number of VCO Phase offsets between BCLK and SCLK
  [2:0] ADDCMD_OFFSET — Number of VCO Phase offsets between REFCLK and ADDCMD bits
0x8D4 TIP_VREF_PARAM — TIP STATIC PARAMETERS 1
  [16:9] CA_VREF — COMMAND/ADDRESS memory VREF
  [8:1] DATA_VREF — DATA memory VREF
  [0] VREF_OVERRIDE — Override VREF default value
0x8D8 LANE_ALIGNMENT_FIFO_CONTROL reset 0x2 — Control signals for lane alignment FIFO
  [1] FIFO_RESET_N — Reset lane alignment FIFO
  [0] BLOCK_FIFO — Block FIFO from receiving data valid pulses
0xC00 SOFT_RESET_SGMII — SGMII Reset control (SEU)
  [31:16] BLOCKID_SGMII ro — not used
  [8] PERIPH_SGMII — assert peripheral block resets
  [1] V_MAP_SGMII — not used
  [0] NV_MAP_SGMII — reset all the RW-P register bits in this map
0xC04 SGMII_MODE reset 0x40E60C — SGMII mode control (SEU)
  [31] REG_REFCLK_EN_INS_HYST_N — REFCLK N input hysterisis enable
  [30] REG_REFCLK_EN_UDRIVE_N — REFCLK N input drive enable
  [29] REG_REFCLK_EN_INS_HYST_P — REFCLK P input hysterisis enable
  [28] REG_REFCLK_EN_UDRIVE_P — REFCLK P input drive enable
  [27:24] REG_BC_VS — GPIO Calibrator modes for normal IOs
  [23] REG_REFCLK_EN_RDIFF — REFCLK input pad enable differential mode
  [22] REG_CDR_MOVE_STEP — CDR jump step 3 or 2, default 3
  [21:16] REG_BC_VRGEN — Bank controller voltage reference modes
  [15] REG_RX1_CDR_RESET_B — RX1 CDR data input start if 1
  [14] REG_RX0_CDR_RESET_B — RX0 CDR data input start if 1
  [13:10] REG_DLL_ADJ_CODE — Add 9 taps to DLL delay code to compensate for generic mux delay
  [9:8] REG_DLL_LOCK_FLT — DLL phase lock tolerance of gitter
  [7] REG_RX1_EN — enable RX1 channel
  [6] REG_TX1_EN — enable TX1 channel
  [5] REG_RX0_EN — enable RX0 channel
  [4] REG_TX0_EN — enable TX0 channel
  [3] REG_BC_VRGEN_EN — enable Bank Controller Vref
  [2] REG_PVT_EN — enable GPIO PVT calibrator by releasing calib_reset
  [1] REG_DLL_EN — enable DLL
  [0] REG_PLL_EN — enable PLL
0xC08 PLL_CNTL reset 0x80140101 — PLL control register (SEU)
  [31:30] REG_PLL_BWP — PLL proportional path loop bandwidth control
  [29:28] REG_PLL_BWI — PLL integral path loop bandwidth control
  [27:16] REG_PLL_INTIN — PLL feedback multiplier (multiplied by 20)
  [15] REG_PLL_LP_REQUIRES_LOCK — PLL lock to exit flash-freeze
  [14] REG_PLL_REG_RFCLK_SEL — PLL select refclk0 by default
  [13:8] REG_PLL_RFDIV — PLL reference clock division
  [7] ARO_PLL0_LOCK ro — PLL lock from SCB
  [6:0] REG_PLL_POSTDIV — PLL post-division for all four outputs (divided by 4)
0xC0C CH0_CNTL reset 0x9C0000 — Channel0 control register
  [30:28] REG_RX0_ODT_STATIC_P — RX0 termination modes
  [27:24] REG_RX0_ODT_P — RX0 termination modes
  [23:21] REG_RX0_EYEWIDTH_P — RX0 eye monitor width
  [20:18] REG_RX0_IBUFMD_P — RX0 pad input buffer mode
  [17] REG_RX0_WPD_P — RX0 pad weak pull-down
  [16] REG_RX0_WPU_P — RX0 pad weak pull-up
  [15] REG_RX0_TIM_LONG — RX0 comma detection timeout long (1) or short (0), 8ms or 1ms
  [14:12] REG_TX0_ODT_STATIC_P — TX0 termination modes
  [11:8] REG_TX0_ODT_P — TX0 termination modes
  [7:4] REG_TX0_DRV_P — TX0 drive strength
  [3:2] REG_TX0_SLEW_P — TX0 pad slew mode
  [1] REG_TX0_WPD_P — TX0 pad weak pull-down
  [0] REG_TX0_WPU_P — TX0 pad weak pull-up
0xC10 CH1_CNTL reset 0x9C0000 — Channel1 control register
  [30:28] REG_RX1_ODT_STATIC_P — RX1 termination modes
  [27:24] REG_RX1_ODT_P — RX1 termination modes
  [23:21] REG_RX1_EYEWIDTH_P — RX1 eye monitor width
  [20:18] REG_RX1_IBUFMD_P — RX1 pad input buffer mode
  [17] REG_RX1_WPD_P — RX1 pad weak pull-down
  [16] REG_RX1_WPU_P — RX1 pad weak pull-up
  [15] REG_RX1_TIM_LONG — RX1 comma detection timeout long (1) or short (0), 8ms or 1ms
  [14:12] REG_TX1_ODT_STATIC_P — TX1 termination modes
  [11:8] REG_TX1_ODT_P — TX1 termination modes
  [7:4] REG_TX1_DRV_P — TX1 drive strength
  [3:2] REG_TX1_SLEW_P — TX1 pad slew mode
  [1] REG_TX1_WPD_P — TX1 pad weak pull-down
  [0] REG_TX1_WPU_P — TX1 pad weak pull-up
0xC14 RECAL_CNTL reset 0x8 — Recalibration control register
  [31] SRO_RECAL_START ro — recalibration interrupt when difference range is exceeded
  [30:24] SRO_DLL_ST_CODE ro — stored DLL code since the last recalibration
  [23] SRO_DLL_LOCK ro — DLL lock
  [22:16] SRO_DLL_90_CODE ro — DLL delay code for 90 degree
  [15:14] REG_PVT_REG_CALIB_DIFFR_VSEL — GPIO Calibrator modes for differential IOs
  [13:12] REG_PVT_REG_CALIB_CLKDIV — GPIO Calibrator clock divider after power-up
  [11] BC_VRGEN_MOVE — Bank Controller voltage reference move
  [10] BC_VRGEN_LOAD — Bank Controller voltage reference load
  [9] BC_VRGEN_DIRECTION — Bank Controller voltage reference move direction
  [8] REG_RECAL_UPD — update dll_st_code when written 1 after recalibration
  [7] REG_PVT_CALIB_LOCK — PVT calibration lock in new code
  [6] REG_PVT_CALIB_START — PVT calibration start new run
  [5] REG_RECAL_START_EN — recalibration interrupt enable
  [4:0] REG_RECAL_DIFF_RANGE — recalibration difference range between dll_90_code and dll_st_code
0xC18 CLK_CNTL reset 0xF0000000 — Clock input and routing control registers
  [31:16] REG_CLKMUX_SPARE0 — spare SEU registers
  [15:14] REG_CLKMUX_PLL0_RFCLK1_SEL — PLL reference clock input1 selection
  [13:12] REG_CLKMUX_PLL0_RFCLK0_SEL — PLL reference clock input0 selection
  [11:9] REG_CLKMUX_FCLK_SEL — SGMII clock selection for fabric
  [8] REG_REFCLK_CLKBUF_EN_PULLUP — REFCLK input pad enable pullup
  [7:6] REG_REFCLK_EN_RXMODE_N — REFCLK N input mode enable
  [5:4] REG_REFCLK_EN_TERM_N — REFCLK N input termination enable
  [3:2] REG_REFCLK_EN_RXMODE_P — REFCLK P input mode enable
  [1:0] REG_REFCLK_EN_TERM_P — REFCLK P input termination enable
0xC1C DYN_CNTL reset 0x400 — Dynamic control registers
  [31:28] ARO_REF_DIFFR ro — PVT DIFFR calibration code from SCB
  [3n+18:3n+16] ARO_PLL0_VCO{n}PH_SEL ro (n=0..3) — PLL VCO phase{n} selection
  [15] PVT_CALIB_STATUS ro — PVT calibration status
  [14] REG_LANE1_SOFT_RESET_PERIPH — Lane1 soft reset
  [13] REG_LANE0_SOFT_RESET_PERIPH — Lane0 soft reset
  [12] REG_CLKMUX_SOFT_RESET_PERIPH — CLKMUX soft reset
  [11] REG_BC_SOFT_RESET_PERIPH — Bank controller soft reset
  [10] REG_PVT_SOFT_RESET_PERIPH — PVT soft reset
  [9] REG_DLL_SOFT_RESET_PERIPH — DLL soft reset
  [8] REG_PLL_SOFT_RESET_PERIPH — PLL soft reset
  [7] BC_VRGEN_OOR ro — Bank controller voltage reference out of range
  [6] REG_LANE1_DYNEN — Lane1 dynamic control enable
  [5] REG_LANE0_DYNEN — Lane0 dynamic control enable
  [4] REG_CLKMUX_DYNEN — CLKMUX dynamic control enable
  [3] REG_BC_DYNEN — Bank controller dynamic control enable
  [2] REG_PVT_DYNEN — PVT calibrator dynamic control enable
  [1] REG_DLL_DYNEN — DLL dynamic control enable
  [0] REG_PLL_DYNEN — PLL dynamic control enable
0xC20 PVT_STAT reset 0x80000000 — PVT calibrator status registers
  [31] PVT_CALIB_START — PVT calibration start new run
  [30] PVT_CALIB_LOCK — PVT calibration lock in new code
  [29:24] ARO_NCODE ro — PVT calibrator N-code to IO lane
  [23] PVT_CALIB_INTRPT ro — PVT calibration interrupt
  [22] ARO_CALIB_INTRPT ro — PVT calibration interrupt
  [21:16] ARO_PCODE ro — PVT calibrator P-code to IO lane
  [15] ARO_CALIB_STATUS_B ro — PVT calibration status_b
  [14] ARO_CALIB_STATUS ro — PVT calibration status
  [13:8] ARO_REF_NCODE ro — PVT calibrator N-code to reference
  [7] ARO_IOEN_BNK_B ro — PVT calibrator IOEN_B
  [6] ARO_IOEN_BNK ro — PVT calibrator IOEN
  [5:0] ARO_REF_PCODE ro — PVT calibrator P-code to reference
0xC24 SPARE_CNTL reset 0xFF000000 — Spare control register
  [31:0] REG_SPARE — spare SEU registers
0xC28 SPARE_STAT ro — Spare status register
  [31:0] SRO_SPARE — spare status bits
